# STM32H573 register map
File version: 1.8
CPU: CM33 r0p0, little endian, MPU, FPU, 4 interrupt priority bits
Registers are 32-bit, read-write, reset 0x0 unless marked. A register's access mark holds for its fields unless they carry their own. Offsets are from the block's base; [hi:lo] are bit positions; lines under a group give offsets from that group; {n}, {i} and the like mark numbered series; 'fields as' and 'values as' point back to an identical list.

## GPDMA1 — General purpose direct memory access controller
Base 0x40020000
Same registers: GPDMA2 0x40021000, SEC_GPDMA1 0x50020000, SEC_GPDMA2 0x50021000
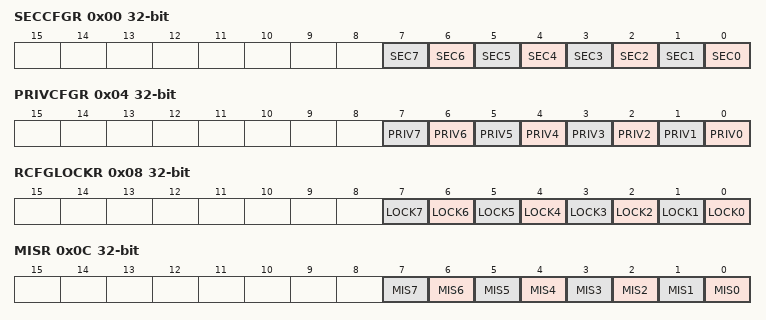
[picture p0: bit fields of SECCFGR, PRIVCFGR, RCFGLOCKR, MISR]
0x00 SECCFGR — GPDMA secure configuration register
  [n] SEC{n} (n=0..7) — secure state of channel x (x = 7 to 0)
0x04 PRIVCFGR — GPDMA privileged configuration register
  [n] PRIV{n} (n=0..7) — privileged state of channel x (x = 7 to 0)
    0=Unprivileged (Channel is unprivileged); 1=Privileged (Channel is privileged)
0x08 RCFGLOCKR — GPDMA configuration lock register
  [n] LOCK{n} (n=0..7) — lock the configuration of GPDMA_SECCFGR.SECx and GPDMA_PRIVCFGR.PRIVx, until a global GPDMA reset (x = 7 to 0) This bit is cleared after reset and, once set, it cannot be reset until a global GPDMA reset.
0x0C MISR ro — GPDMA non-secure masked interrupt status register
  [n] MIS{n} (n=0..7) — masked interrupt status of channel x (x = 7 to 0)
    0=NoTrigger (No interrupt has occurred on channel); 1=Trigger (An interrupt has occurred on channel)
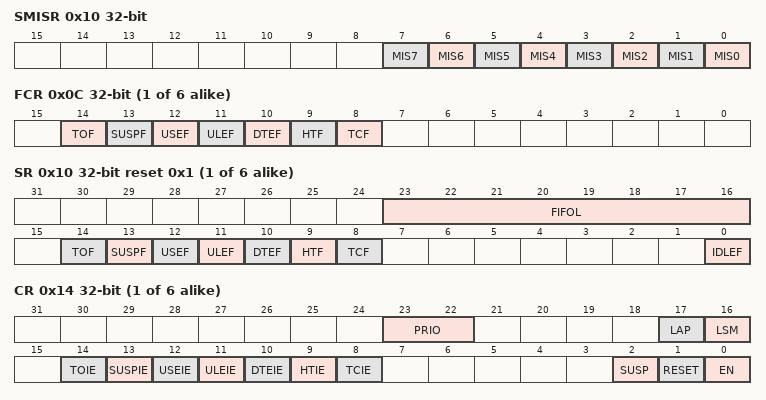
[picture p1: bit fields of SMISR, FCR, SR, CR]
0x10 SMISR ro — GPDMA secure masked interrupt status register
  [n] MIS{n} (n=0..7) — masked interrupt status of the secure channel x (x = 7 to 0)
{0x50+0x80*i} CH{i} (i=0..5) group — Channel cluster
  0x00 LBAR — GPDMA channel 0 linked-list base address register
    [31:16] LBA — linked-list base address of GPDMA channel x
  0x0C FCR wo — GPDMA channel 0 flag clear register
    [all] fields
      1=Clear flag
    [14] TOF — trigger overrun flag clear
    [13] SUSPF — completed suspension flag clear
    [12] USEF — user setting error flag clear
    [11] ULEF — update link transfer error flag clear
    [10] DTEF — data transfer error flag clear
    [9] HTF — half transfer flag clear
    [8] TCF — transfer complete flag clear
  0x10 SR ro reset 0x1 — GPDMA channel 0 status register
    [23:16] FIFOL — monitored FIFO level Number of available write beats in the FIFO, in units of the programmed destination data width (see GPDMA_CxTR1.DDW_LOG2[1:0], in units of bytes, half-words, or words). Note: After having suspended an active transfer, the user may need to read FIFOL[7:0], additionally to GPDMA_CxBR1.BDNT[15:0] and GPDMA_CxBR1.BRC[10:0], to know how many data have been transferred to the destination. Before reading, the user may wait for the transfer to be suspended (GPDMA_CxSR.SUSPF = 1).
    [14] TOF — trigger overrun flag
      0=NoTrigger (Event not triggered); 1=Trigger (Event triggered)
    [13] SUSPF — completed suspension flag
      values as TOF
    [12] USEF — user setting error flag
      values as TOF
    [11] ULEF — update link transfer error flag
      values as TOF
    [10] DTEF — data transfer error flag
      values as TOF
    [9] HTF — half transfer flag A half transfer event is either a half block transfer or a half 2D/repeated block transfer, depending on the transfer complete event mode (GPDMA_CxTR2.TCEM[1:0]). A half block transfer occurs when half of the bytes of the source block size (rounded up integer of GPDMA_CxBR1.BNDT[15:0]/2) has been transferred to the destination. A half 2D/repeated block transfer occurs when half of the repeated blocks (rounded up integer of (GPDMA_CxBR1.BRC[10:0]+1)/2)) has been transferred to the destination.
      values as TOF
    [8] TCF — transfer complete flag A transfer complete event is either a block transfer complete, a 2D/repeated block transfer complete, a LLI transfer complete including the upload of the next LLI if any, or the full linked-list completion, depending on the transfer complete event mode (GPDMA_CxTR2.TCEM[1:0]).
      values as TOF
    [0] IDLEF — idle flag This idle flag is de-asserted by hardware when the channel is enabled (GPDMA_CxCR.EN = 1) with a valid channel configuration (no USEF to be immediately reported). This idle flag is asserted after hard reset or by hardware when the channel is back in idle state (in suspended or disabled state).
      values as TOF
  0x14 CR access per field — GPDMA channel 0 control register
    [23:22] PRIO rw — priority level of the channel x GPDMA transfer versus others Note: This bit must be written when EN = 0. This bit is read-only when EN = 1.
      0=LowPrioLowWeight (Low priority, low weight); 1=LowPrioMidWeight (Low priority, mid weight); 2=LowPrioHighWeight (Low priority, high weight); 3=High priority
    [17] LAP rw — linked-list allocated port This bit is used to allocate the master port for the update of the GPDMA linked-list registers from the memory. Note: This bit must be written when EN=0. This bit is read-only when EN=1.
      0=Port 0 (AHB) allocated; 1=Port 1 (AHB) allocated
    [16] LSM rw — Link step mode First the (possible 1D/repeated) block transfer is executed as defined by the current internal register file until GPDMA_CxBR1.BNDT[15:0] = 0 and GPDMA_CxBR1.BRC[10:0] = 0 if present. Secondly the next linked-list data structure is conditionally uploaded from memory as defined by GPDMA_CxLLR. Then channel execution is completed. Note: This bit must be written when EN=0. This bit is read-only when EN=1.
      0=FullLinkedList (Channel executed for full linked list); 1=Once (Channel executed once for current linked list)
    [14] TOIE rw — trigger overrun interrupt enable
      0=Disabled (Interrupt disabled); 1=Enabled (Interrupt enabled)
    [13] SUSPIE rw — completed suspension interrupt enable
      values as TOIE
    [12] USEIE rw — user setting error interrupt enable
      values as TOIE
    [11] ULEIE rw — update link transfer error interrupt enable
      values as TOIE
    [10] DTEIE rw — data transfer error interrupt enable
      values as TOIE
    [9] HTIE rw — half transfer complete interrupt enable
      values as TOIE
    [8] TCIE rw — transfer complete interrupt enable
      values as TOIE
    [2] SUSP rw — suspend Writing 1 into the field RESET (bit 1) causes the hardware to de-assert this bit, whatever is written into this bit 2. Else: Software must write 1 in order to suspend an active channel i.e. a channel with an ongoing GPDMA transfer over its master ports. The software must write 0 in order to resume a suspended channel, following the programming sequence detailed in .
      0=NotSuspended (Channel operation not suspended); 1=Suspended (Channel operation suspended)
    [1] RESET wo — reset This bit is write only. Writing 0 has no impact. Writing 1 implies the reset of the following: the FIFO, the channel internal state, SUSP and EN bits (whatever is written receptively in bit 2 and bit 0). The reset is effective when the channel is in steady state, meaning one of the following: - active channel in suspended state (GPDMA_CxSR.SUSPF = 1 and GPDMA_CxSR.IDLEF = GPDMA_CxCR.EN = 1) - channel in disabled state (GPDMA_CxSR.IDLEF = 1 and GPDMA_CxCR.EN = 0). After writing a RESET, to continue using this channel, the user must explicitly reconfigure the channel including the hardware-modified configuration registers (GPDMA_CxBR1, GPDMA_CxSAR and GPDMA_CxDAR) before enabling again the channel (see the programming sequence in ).
      1=Reset channel
    [0] EN rw — enable Writing 1 into the field RESET (bit 1) causes the hardware to de-assert this bit, whatever is written into this bit 0. Else: this bit is de-asserted by hardware when there is a transfer error (master bus error or user setting error) or when there is a channel transfer complete (channel ready to be configured, e.g. if LSM=1 at the end of a single execution of the LLI). Else, this bit can be asserted by software. Writing 0 into this EN bit is ignored.
      0=Disabled (Channel disabled); 1=Enabled (Channel enabled)
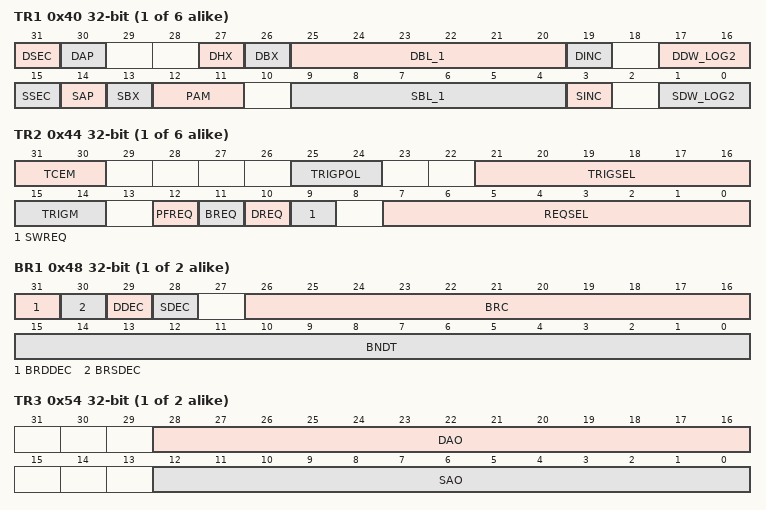
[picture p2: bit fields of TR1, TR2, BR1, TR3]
  0x40 TR1 — GPDMA channel 0 transfer register 1
    [31] DSEC — security attribute of the GPDMA transfer to the destination If GPDMA_SECCFGR.SECx = 1 and the access is secure: This is a secure register bit. This bit can only be read by a secure software. This bit must be written by a secure software when GPDMA_SECCFGR.SECx = 1. A secure write is ignored when GPDMA_SECCFGR.SECx = 0. When GPDMA_SECCFGR.SECx is de-asserted, this DSEC bit is also de-asserted by hardware (on a secure reconfiguration of the channel as non-secure), and the GPDMA transfer to the destination is non-secure.
    [30] DAP — destination allocated port This bit is used to allocate the master port for the destination transfer Note: This bit must be written when EN = 0. This bit is read-only when EN = 1.
      0=Port 0 (AHB) allocated; 1=Port 1 (AHB) allocated
    [27] DHX — destination half-word exchange If the destination data size is shorter than a word, this bit is ignored. If the destination data size is a word:
      0=NotExchanged (No halfword-based exchange within word); 1=Exchanged (The two consecutive (post PAM) half-words are exchanged in each destination word)
    [26] DBX — destination byte exchange If the destination data size is a byte, this bit is ignored. If the destination data size is not a byte:
      0=NotExchanged (No byte-based exchanged within word); 1=Exchanged (The two consecutive (post PAM) bytes are exchanged in each destination half-word)
    [25:20] DBL_1 — destination burst length minus 1, between 0 and 63 The burst length unit is one data named beat within a burst. If DBL_1[5:0] =0 , the burst can be named as single. Each data/beat has a width defined by the destination data width DDW_LOG2[1:0]. Note: If a burst transfer crossed a 1-Kbyte address boundary on a AHB transfer, the GPDMA modifies and shortens the programmed burst into singles or bursts of lower length, to be compliant with the AHB protocol. If a burst transfer is of length greater than the FIFO size of the channel x, the GPDMA modifies and shortens the programmed burst into singles or bursts of lower length, to be compliant with the FIFO size. Transfer performance is lower, with GPDMA re-arbitration between effective and lower singles/bursts, but the data integrity is guaranteed.
    [19] DINC — destination incrementing burst The destination address, pointed by GPDMA_CxDAR, is kept constant after a burst beat/single transfer, or is incremented by the offset value corresponding to a contiguous data after a burst beat/single transfer.
      0=FixedBurst; 1=Contiguously incremented burst
    [17:16] DDW_LOG2 — binary logarithm of the destination data width of a burst, in bytes Note: Setting a 8-byte data width causes a user setting error to be reported and none transfer is issued. A destination burst transfer must have an aligned address with its data width (start address GPDMA_CxDAR[2:0] and address offset GPDMA_CxTR3.DAO[2:0], versus DDW_LOG2[1:0]). Otherwise a user setting error is reported and no transfer is issued.
      on read: 0=Byte; 1=Half-word (2 bytes); 2=Word (4 bytes); 3=Error (User setting error) | on write: 0=Byte; 1=Half-word (2 bytes); 2=Word (4 bytes)
    [15] SSEC — security attribute of the GPDMA transfer from the source If GPDMA_SECCFGR.SECx = 1 and the access is secure: This is a secure register bit. This bit can only be read by a secure software. This bit must be written by a secure software when GPDMA_SECCFGR.SECx =1 . A secure write is ignored when GPDMA_SECCFGR.SECx = 0. When GPDMA_SECCFGR.SECx is de-asserted, this SSEC bit is also de-asserted by hardware (on a secure reconfiguration of the channel as non-secure), and the GPDMA transfer from the source is non-secure.
    [14] SAP — source allocated port This bit is used to allocate the master port for the source transfer Note: This bit must be written when EN = 0. This bit is read-only when EN = 1.
      0=Port 0 (AHB) allocated; 1=Port 1 (AHB) allocated
    [13] SBX — source byte exchange within the unaligned half-word of each source word If the source data width is shorter than a word, this bit is ignored. If the source data width is a word:
      values as DBX
    [12:11] PAM — padding/alignment mode If DDW_LOG2[1:0] = SDW_LOG2[1:0]: if the data width of a burst destination transfer is equal to the data width of a burst source transfer, these bits are ignored. Else, in the following enumerated values, the condition PAM_1 is when destination data width is higher that source data width, and the condition PAM_2 is when destination data width is higher than source data width. 1x: successive source data are FIFO queued and packed at the destination data width, in a left (LSB) to right (MSB) order (named little endian), before a destination transfer 1x: source data is FIFO queued and unpacked at the destination data width, to be transferred in a left (LSB) to right (MSB) order (named little endian) to the destination Note: If the transfer from the source peripheral is configured with peripheral flow-control mode (SWREQ = 0 and PFREQ = 1 and DREQ = 0), and if the destination data width the source data width, packing is not supported.
    [9:4] SBL_1 — source burst length minus 1, between 0 and 63 The burst length unit is one data named beat within a burst. If SBL_1[5:0] =0 , the burst can be named as single. Each data/beat has a width defined by the destination data width SDW_LOG2[1:0]. Note: If a burst transfer crossed a 1-Kbyte address boundary on a AHB transfer, the GPDMA modifies and shortens the programmed burst into singles or bursts of lower length, to be compliant with the AHB protocol. If a burst transfer is of length greater than the FIFO size of the channel x, the GPDMA modifies and shortens the programmed burst into singles or bursts of lower length, to be compliant with the FIFO size. Transfer performance is lower, with GPDMA re-arbitration between effective and lower singles/bursts, but the data integrity is guaranteed.
    [3] SINC — source incrementing burst The source address, pointed by GPDMA_CxSAR, is kept constant after a burst beat/single transfer or is incremented by the offset value corresponding to a contiguous data after a burst beat/single transfer.
      0=FixedBurst; 1=Contiguously incremented burst
    [1:0] SDW_LOG2 — binary logarithm of the source data width of a burst in bytes Note: Setting a 8-byte data width causes a user setting error to be reported and no transfer is issued. A source block size must be a multiple of the source data width (GPDMA_CxBR1.BNDT[2:0] versus SDW_LOG2[1:0]). Otherwise, a user setting error is reported and no transfer is issued. A source burst transfer must have an aligned address with its data width (start address GPDMA_CxSAR[2:0] versus SDW_LOG2[1:0]). Otherwise, a user setting error is reported and none transfer is issued.
      values as DDW_LOG2
  0x44 TR2 — GPDMA channel 0 transfer register 2
    [31:30] TCEM — transfer complete event mode These bits define the transfer granularity for the transfer complete and half transfer complete events generation. Note: If the initial LLI0 data transfer is null/void (directly programmed by the internal register file with GPDMA_CxBR1.BNDT[15:0] = 0), then neither the complete transfer event nor the half transfer event is generated. Note: If the initial LLI0 data transfer is null/void (directly programmed by the internal register file with GPDMA_CxBR1.BNDT[15:0] = 0), then neither the complete transfer event nor the half transfer event is generated. Note: If the initial LLI0 data transfer is null/void (i.e. directly programmed by the internal register file with GPDMA_CxBR1.BNDT[15:0] =0 ), then the half transfer event is not generated, and the transfer complete event is generated when is completed the loading of the LLI1.
      0=BlockLevel (At block level: the complete (and the half) transfer event is generated at the (respectively half of the) end of a block); 2=LliLevel (At LLI level: the complete transfer event is generated at the end of the LLI transfer. The half transfer event is generated at the half of the LLI data transfer); 3=ChannelLevel (At channel level: the complete transfer event is generated at the end of the last LLI transfer. The half transfer event is generated at the half of the data transfer of the last LLI)
    [25:24] TRIGPOL — trigger event polarity These bits define the polarity of the selected trigger event input defined by TRIGSEL[5:0].
      0=NoTrigger; 1=RisingEdge (Trigger on rising edge); 2=FallingEdge (Trigger on falling edge)
    [21:16] TRIGSEL — trigger event input selection These bits select the trigger event input of the GPDMA transfer (as per ), with an active trigger event if TRIGPOL[1:0] different 00.
      {v}=EXTI{v} (exti{v} is trigger input) (v=0..7); 8=TAMP_TRG1 (tamp_trg1 is trigger input); 9=TAMP_TRG2 (tamp_trg2 is trigger input); 11=LPTIM1_CH1 (lptim1_ch1 is trigger input); 12=LPTIM1_CH2 (lptim1_ch2 is trigger input); 13=LPTIM2_CH1 (lptim2_ch1 is trigger input); 14=LPTIM2_CH2 (lptim2_ch2 is trigger input); 15=RTC_ALRA_TRG (rtc_alra_trg is trigger input); 16=RTC_ALRB_TRG (rtc_alrb_trg is trigger input); 17=RTC_WUT_TRG (rtc_wut_trg is trigger input); {v}=GPDMA1_CH{v-18}_TC (gpdma1_ch{v-18}_tc is trigger input) (v=18..25); {v}=GPDMA2_CH{v-26}_TC (gpdma2_ch{v-26}_tc is trigger input) (v=26..33); 34=TIM2_TRG0 (tim2_trgo is trigger input); 44=COMP1_OUT (comp1_out is trigger input)
    [15:14] TRIGM — trigger mode These bits define the transfer granularity for its conditioning by the trigger. If the channel x is enabled (GPDMA_CxCR.EN asserted) with TRIGPOL[1:0] = 00 or 11, these TRIGM[1:0] bits are ignored. Else, a GPDMA transfer is conditioned by at least one trigger hit: first burst read of a 2D/repeated block transfer is conditioned by one hit trigger. If the peripheral is programmed as a source (DREQ = 0) of the LLI data transfer, each programmed burst read is conditioned. If the peripheral is programmed as a destination (DREQ = 1) of the LLI data transfer, each programmed burst write is conditioned. The first memory burst read of a (possibly 2D/repeated) block, also named as the first ready FIFO-based source burst, is gated by the occurrence of both the hardware request and the first trigger hit. The GPDMA monitoring of a trigger for channel x is started when the channel is enabled/loaded with a new active trigger configuration: rising or falling edge on a selected trigger (TRIGPOL[1:0] = 01 or respectively TRIGPOL[1:0] = 10). The monitoring of this trigger is kept active during the triggered and uncompleted (data or link) transfer; and if a new trigger is detected then, this hit is internally memorized to grant the next transfer, as long as the defined rising or falling edge is not modified, and the TRIGSEL[5:0] is not modified, and the channel is enabled. Transferring a next LLIn+1 that updates the GPDMA_CxTR2 with a new value for any of TRIGSEL[5:0] or TRIGPOL[1:0], resets the monitoring, trashing the memorized hit of the formerly defined LLIn trigger. After a first new trigger hitn+1 is memorized, if another second trigger hitn+2 is detected and if the hitn triggered transfer is still not completed, hitn+2 is lost and not memorized.memorized. A trigger overrun flag is reported (GPDMA_CxSR.TOF =1 ), and an interrupt is generated if enabled (GPDMA_CxCR.TOIE = 1). The channel is not automatically disabled by hardware due to a trigger overrun. Note: When the source block size is not a multiple of the source burst size and is a multiple of the source data width, then the last programmed source burst is not completed and is internally shorten to match the block size. In this case, if TRIGM[1:0] = 11 and (SWREQ =1 or (SWREQ = 0 and DREQ =0 )), the shortened burst transfer (by singles or/and by bursts of lower length) is conditioned once by the trigger. When the programmed destination burst is internally shortened by singles or/and by bursts of lower length (versus FIFO size, versus block size, 1-Kbyte boundary address crossing): if the trigger is conditioning the programmed destination burst (if TRIGM[1:0] = 11 and SWREQ = 0 and DREQ = 1), this shortened destination burst transfer is conditioned once by the trigger.
      0=BlockLevel (At block level: the first burst read of each block transfer is conditioned by one hit trigger); 2=LinkLevel (At link level: a LLI link transfer is conditioned by one hit trigger); 3=ProgrammedBurstLevel (At programmed burst level: programmed burst read is conditioned by one hit trigger.)
    [12] PFREQ — Hardware request in peripheral flow control mode Important: If a given channel x is not implemented with this feature, this bit is reserved and PFREQ is not present (see for the list of the implemented channels with this feature. If the channel x is activated (GPDMA_CxCR.EN asserted) with SWREQ = 1 (software request for a memory-to-memory transfer), this bit is ignored. Else: Note: In peripheral flow control mode, there are the following restrictions: - no 2D/repeated block support (GPDMA_CxBR1.BRC[10:0] must be set to 0 if present) - the peripheral must be set as the source of the transfer (DREQ = 0). - data packing to a wider destination width is not supported (if destination width source data width, GPDMA_CxTR1.PAM[1] must be set to 0). - GPDMA_CxBR1.BNDT[15:0] must be programmed as a multiple of the source (peripheral) burst size.
      0=GpdmaControlMode (The selected hardware request is driven by a peripheral with a hardware request/acknowledge protocol in GPDMA control mode); 1=PeripheralControlMode (The selected hardware request is driven by a peripheral with a hardware request/acknowledge protocol in peripheral control mode.)
    [11] BREQ — Block hardware request If the channel x is activated (GPDMA_CxCR.EN asserted) with SWREQ = 1 (software request for a memory-to-memory transfer), this bit is ignored. Else:
      0=Burst (The selected hardware request is driven by a peripheral with a hardware request/acknowledge protocol at a burst level); 1=Block (The selected hardware request is driven by a peripheral with a hardware request/acknowledge protocol at a block level)
    [10] DREQ — destination hardware request This bit is ignored if channel x is activated (GPDMA_CxCR.EN asserted) with SWREQ = 1 (software request for a memory-to-memory transfer). Else: Note: If the channel x is activated (GPDMA_CxCR.EN is asserted) with SWREQ = 0 and PFREQ = 1 (peripheral hardware request with peripheral flow-control mode), any software assertion to this DREQ bit is ignored: in peripheral flow-control mode, only a peripheral-to-memory transfer is supported.
      0=Source (Selected hardware request driven by a source peripheral); 1=Destination (Selected hardware request driven by a destination peripheral)
    [9] SWREQ — software request This bit is internally taken into account when GPDMA_CxCR.EN is asserted.
      0=Hardware (No software request. The selected hardware request REQSEL[7:0] is taken into account); 1=Software request for memory-to-memory transfer
    [7:0] REQSEL — GPDMA hardware request selection These bits are ignored if channel x is activated (GPDMA_CxCR.EN asserted) with SWREQ = 1 (software request for a memory-to-memory transfer). Else, the selected hardware request is internally taken into account as per . The user must not assign a same input hardware request (same REQSEL[7:0] value) to different active GPDMA channels (GPDMA_CxCR.EN = 1 and GPDMA_CxTR2.SWREQ = 0 for these channels). GPDMA is not intended to hardware support the case of simultaneous enabled channels incorrectly configured with a same hardware peripheral request signal, and there is no user setting error reporting.
      0=ADC1_DMA (adc1_dma selected); 2=DAC1_CH1_DMA (dac1_ch1_dma selected); 3=DAC1_CH2_DMA (dac1_ch2_dma selected); 4=TIM6_UPD_DMA (tim6_upd_dma selected); 5=TIM7_UPD_DMA (tim7_upd_dma selected); 6=SPI1_RX_DMA (spi1_rx_dma selected); 7=SPI1_TX_DMA (spi1_tx_dma selected); 8=SPI2_RX_DMA (spi2_rx_dma selected); 9=SPI2_TX_DMA (spi2_tx_dma selected); 10=SPI3_RX_DMA (spi3_rx_dma selected); 11=SPI3_TX_DMA (spi3_tx_dma selected); 12=I2C1_RX_DMA (i2c1_rx_dma selected); 13=I2C1_TX_DMA (i2c1_tx_dma selected); 15=I2C2_RX_DMA (i2c2_rx_dma selected); 16=I2C2_TX_DMA (i2c2_tx_dma selected); 18=I2C3_RX_DMA (i2c3_rx_dma selected); 19=I2C3_TX_DMA (i2c3_tx_dma selected); 21=USART1_RX_DMA (usart1_rx_dma selected); 22=USART1_TX_DMA (usart1_tx_dma selected); 23=USART2_RX_DMA (usart2_rx_dma selected); 24=USART2_TX_DMA (usart2_tx_dma selected); 25=USART3_RX_DMA (usart3_rx_dma selected); 26=USART3_TX_DMA (usart3_tx_dma selected); 27=UART4_RX_DMA (uart4_rx_dma selected); 28=UART4_TX_DMA (uart4_tx_dma selected); 29=UART5_RX_DMA (uart5_rx_dma selected); 30=UART5_TX_DMA (uart5_tx_dma selected); 31=USART6_RX_DMA (usart6_rx_dma selected); 32=USART6_TX_DMA (usart6_tx_dma selected); 33=UART7_RX_DMA (uart7_rx_dma selected); 34=UART7_TX_DMA (uart7_tx_dma selected); 35=UART8_RX_DMA (uart8_rx_dma selected); 36=UART8_TX_DMA (uart8_tx_dma selected); 37=UART9_RX_DMA (uart9_rx_dma selected); 38=UART9_TX_DMA (uart9_tx_dma selected); 39=UART10_RX_DMA (uart10_rx_dma selected); 40=UART10_TX_DMA (uart10_tx_dma selected); 41=UART11_RX_DMA (uart11_rx_dma selected); 42=UART11_TX_DMA (uart11_tx_dma selected); 43=UART12_RX_DMA (uart12_rx_dma selected); 44=UART12_TX_DMA (uart12_tx_dma selected); 45=LPUART1_RX_DMA (lpuart1_rx_dma selected); 46=LPUART1_TX_DMA (lpuart1_tx_dma selected); 47=SPI4_RX_DMA (spi4_rx_dma selected); 48=SPI4_TX_DMA (spi4_tx_dma selected); 49=SPI5_RX_DMA (spi5_rx_dma selected); 50=SPI5_TX_DMA (spi5_tx_dma selected); 51=SPI6_RX_DMA (spi6_rx_dma selected); 52=SPI6_TX_DMA (spi6_tx_dma selected); 53=SAI1_A_DMA (sai1_a_dma selected); 54=SAI1_B_DMA (sai1_b_dma selected); 55=SAI2_A_DMA (sai2_a_dma selected); 56=SAI2_B_DMA (sai2_b_dma selected); 57=OSPI1_DMA (ospi1_dma selected); {v}=TIM1_CC{v-57}_DMA (tim1_cc{v-57}_dma selected) (v=58..61); 62=TIM1_UPD_DMA (tim1_upd_dma selected); 63=TIM1_TRG_DMA (tim1_trg_dma selected); 64=TIM1_COM_DMA (tim1_com_dma selected); {v}=TIM8_CC{v-64}_DMA (tim8_cc{v-64}_dma selected) (v=65..68); 69=TIM8_UPD_DMA (tim8_upd_dma selected); 70=TIM8_TIG_DMA (tim8_tig_dma selected); 71=TIM8_COM_DMA (tim8_com_dma selected); {v}=TIM2_CC{v-71}_DMA (tim2_cc{v-71}_dma selected) (v=72..75); 76=TIM2_UPD_DMA (tim2_upd_dma selected); {v}=TIM3_CC{v-76}_DMA (tim3_cc{v-76}_dma selected) (v=77..80); 81=TIM3_UPD_DMA (tim3_upd_dma selected); 82=TIM3_TRG_DMA (tim3_trg_dma selected); {v}=TIM4_CC{v-82}_DMA (tim4_cc{v-82}_dma selected) (v=83..86); 87=TIM4_UPD_DMA (tim4_upd_dma selected); {v}=TIM5_CC{v-87}_DMA (tim5_cc{v-87}_dma selected) (v=88..91); 92=TIM5_UPD_DMA (tim5_upd_dma selected); 93=TIM5_TRG_DMA (tim5_trg_dma selected); 94=TIM15_CC1_DMA (tim15_cc1_dma selected); 95=TIM15_UPD_DMA (tim15_upd_dma selected); 96=TIM15_TRG_DMA (tim15_trg_dma selected); 97=TIM15_COM_DMA (tim15_com_dma selected); 98=TIM16_CC1_DMA (tim16_cc1_dma selected); 99=TIM16_UPD_DMA (tim16_upd_dma selected); 100=TIM17_CC1_DMA (tim17_cc1_dma selected); 101=TIM17_UPD_DMA (tim17_upd_dma selected); 102=LPTIM1_IC1_DMA (lptim1_ic1_dma selected); 103=LPTIM1_IC2_DMA (lptim1_ic2_dma selected); 104=LPTIM1_UE_DMA (lptim1_ue_dma selected); 105=LPTIM2_IC1_DMA (lptim2_ic1_dma selected); 106=LPTIM2_IC2_DMA (lptim2_ic2_dma selected); 107=LPTIM2_UE_DMA (lptim2_ue_dma selected); 108=DCMI_PSSI_DMA (dcmi_dma or pssi_dma(1) selected); 109=AES_OUT_DMA (aes_out_dma selected); 110=AES_IN_DMA (aes_in_dma selected); 111=HASH_IN_DMA (hash_in_dma selected); 112=UCPD1_RX_DMA (ucpd1_rx_dma selected); 113=UCPD1_TX_DMA (ucpd1_tx_dma selected); 114=CORDIC_READ_DMA (cordic_read_dma selected); 115=CORDIC_WRITE_DMA (cordic_write_dma selected); 116=FMAC_READ_DMA (fmac_read_dma selected); 117=FMAC_WRITE_DMA (fmac_write_dma selected); 118=SAES_OUT_DMA (saes_out_dma selected); 119=SAES_IN_DMA (saes_in_dma selected); 120=I3C1_RX_DMA (i3c1_rx_dma selected); 121=I3C1_TX_DMA (i3c1_tx_dma selected); 122=I3C1_TC_DMA (i3c1_tc_dma selected); 123=I3C1_RS_DMA (i3c1_rs_dma selected); 124=I2C4_RX_DMA (i2c4_rx_dma selected); 125=I2C4_TX_DMA (i2c4_tx_dma selected); 127=LPTIM3_IC1_DMA (lptim3_ic1_dma selected); 128=LPTIM3_IC2_DMA (lptim3_ic2_dma selected); 129=LPTIM3_UE_DMA (lptim3_ue_dma selected); 130=LPTIM5_IC1_DMA (lptim5_ic1_dma selected); 131=LPTIM5_IC2_DMA (lptim5_ic2_dma selected); 132=LPTIM5_UE_DMA (lptim5_ue_dma selected); 133=LPTIM6_IC1_DMA (lptim6_ic1_dma selected); 134=LPTIM6_IC2_DMA (lptim6_ic2_dma selected); 135=LPTIM6_UE_DMA (lptim6_ue_dma selected); 136=I3C2_RX (i3c2_rx selected); 137=I3C2_TX (i3c2_tx selected); 138=I3C2_TC (i3c2_tc selected); 139=I3C2_RS (i3c2_rs selected)
  0x48 BR1 — GPDMA channel 0 block register 1
    [15:0] BNDT — block number of data bytes to transfer from the source Block size transferred from the source. When the channel is enabled, this field becomes read-only and is decremented, indicating the remaining number of data items in the current source block to be transferred. BNDT[15:0] is programmed in number of bytes, maximum source block size is 64 Kbytes -1. Once the last data transfer is completed (BNDT[15:0] = 0): - if GPDMA_CxLLR.UB1 = 1, this field is updated by the LLI in the memory. - if GPDMA_CxLLR.UB1 = 0 and if there is at least one non null Uxx update bit, this field is internally restored to the programmed value. - if all GPDMA_CxLLR.Uxx = 0 and if GPDMA_CxLLR.LA[15:0] = 0, this field is internally restored to the programmed value (infinite/continuous last LLI). - if GPDMA_CxLLR = 0, this field is kept as zero following the last LLI data transfer. Note: A non-null source block size must be a multiple of the source data width (BNDT[2:0] versus GPDMA_CxTR1.SDW_LOG2[1:0]). Else a user setting error is reported and no transfer is issued. When configured in packing mode (GPDMA_CxTR1.PAM[1] = 1 and destination data width different from source data width), a non-null source block size must be a multiple of the destination data width (BNDT[2:0] versus GPDMA_CxTR1.DDW_LOG2[1:0]). Else a user setting error is reported and no transfer is issued.
  0x4C SAR — GPDMA channel 0 source address register
    [31:0] SA — source address This field is the pointer to the address from which the next data is read. During the channel activity, depending on the source addressing mode (GPDMA_CxTR1.SINC), this field is kept fixed or incremented by the data width (GPDMA_CxTR1.SDW_LOG2[1:0]) after each burst source data, reflecting the next address from which data is read. During the channel activity, this address is updated after each completed source burst, consequently to: the programmed source burst; either in fixed addressing mode or in contiguous-data incremented mode. If contiguously incremented (GPDMA_CxTR1.SINC = 1), then the additional address offset value is the programmed burst size, as defined by GPDMA_CxTR1.SBL_1[5:0] and GPDMA_CxTR1.SDW_LOG2[21:0] the additional source incremented/decremented offset value as programmed by GPDMA_CxBR1.SDEC and GPDMA_CxTR3.SAO[12:0] once/if completed source block transfer, for a channel x with 2D addressing capability (x = 12 to 15). additional block repeat source incremented/decremented offset value as programmed by GPDMA_CxBR1.BRSDEC and GPDMA_CxBR2.BRSAO[15:0] In linked-list mode, after a LLI data transfer is completed, this register is automatically updated by GPDMA from the memory, provided the LLI is set with GPDMA_CxLLR.USA = 1. Note: A source address must be aligned with the programmed data width of a source burst (SA[2:0] versus GPDMA_CxTR1.SDW_LOG2[1:0]). Else, a user setting error is reported and no transfer is issued. When the source block size is not a multiple of the source burst size and is a multiple of the source data width, the last programmed source burst is not completed and is internally shorten to match the block size. In this case, the additional GPDMA_CxTR3.SAO[12:0] is not applied.
  0x50 DAR — GPDMA channel 0 destination address register
    [31:0] DA — destination address This field is the pointer to the address from which the next data is written. During the channel activity, depending on the destination addressing mode (GPDMA_CxTR1.DINC), this field is kept fixed or incremented by the data width (GPDMA_CxTR1.DDW_LOG2[21:0]) after each burst destination data, reflecting the next address from which data is written. During the channel activity, this address is updated after each completed destination burst, consequently to: the programmed destination burst; either in fixed addressing mode or in contiguous-data incremented mode. If contiguously incremented (GPDMA_CxTR1.DINC = 1), then the additional address offset value is the programmed burst size, as defined by GPDMA_CxTR1.DBL_1[5:0] and GPDMA_CxTR1.DDW_LOG2[1:0] the additional destination incremented/decremented offset value as programmed by GPDMA_CxBR1.DDEC and GPDMA_CxTR3.DAO[12:0] once/if completed destination block transfer, for a channel x with 2D addressing capability (x = 12 to 15), the additional block repeat destination incremented/decremented offset value as programmed by GPDMA_CxBR1.BRDDEC and GPDMA_CxBR2.BRDAO[15:0] In linked-list mode, after a LLI data transfer is completed, this register is automatically updated by the GPDMA from the memory, provided the LLI is set with GPDMA_CxLLR.UDA = 1. Note: A destination address must be aligned with the programmed data width of a destination burst (DA[2:0] versus GPDMA_CxTR1.DDW_LOG2[1:0]). Else, a user setting error is reported and no transfer is issued.
  0x7C LLR — GPDMA channel 0 linked-list address register
    [31] UT1 — Update GPDMA_CxTR1 from memory This bit controls the update of GPDMA_CxTR1 from the memory during the link transfer.
      0=NoUpdate (No CxTR1 update); 1=Update (CxTR1 updated from memory during link transfer)
    [30] UT2 — Update GPDMA_CxTR2 from memory This bit controls the update of GPDMA_CxTR2 from the memory during the link transfer.
      0=NoUpdate (No CxTR2 update); 1=Update (CxTR2 updated from memory during link transfer)
    [29] UB1 — Update GPDMA_CxBR1 from memory This bit controls the update of GPDMA_CxBR1 from the memory during the link transfer. If UB1 = 0 and if GPDMA_CxLLR different 0, the linked-list is not completed. GPDMA_CxBR1.BNDT[15:0] is then restored to the programmed value after data transfer is completed and before the link transfer.
      0=NoUpdate (No CxBR1 update); 1=Update (CxBR1 updated from memory during link transfer)
    [28] USA — update GPDMA_CxSAR from memory This bit controls the update of GPDMA_CxSAR from the memory during the link transfer.
      0=NoUpdate (No CxSAR update); 1=Update (CxSAR updated from memory during link transfer)
    [27] UDA — Update GPDMA_CxDAR register from memory This bit is used to control the update of GPDMA_CxDAR from the memory during the link transfer.
      0=NoUpdate (No CxDAR update); 1=Update (CxDAR updated from memory during link transfer)
    [16] ULL — Update GPDMA_CxLLR register from memory This bit is used to control the update of GPDMA_CxLLR from the memory during the link transfer.
      0=NoUpdate (No CxLLR update); 1=Update (CxLLR updated from memory during link transfer)
    [15:2] LA — pointer (16-bit low-significant address) to the next linked-list data structure If UT1 = UT2 = UB1 = USA = UDA = ULL = 0 and if LA[15:20] = 0, the current LLI is the last one. The channel transfer is completed without any update of the linked-list GPDMA register file. Else, this field is the pointer to the memory address offset from which the next linked-list data structure is automatically fetched from, once the data transfer is completed, in order to conditionally update the linked-list GPDMA internal register file (GPDMA_CxCTR1, GPDMA_CxTR2, GPDMA_CxBR1, GPDMA_CxSAR, GPDMA_CxDAR and GPDMA_CxLLR). Note: The user must program the pointer to be 32-bit aligned. The two low-significant bits are write ignored.
{0x50+0x80*i} CH2D{i} (i=6..7) group — 2D-addressing channel cluster
  0x00 LBAR — GPDMA channel 6 linked-list base address register
    [31:16] LBA — linked-list base address of GPDMA channel x
  0x0C FCR wo — GPDMA channel 6 flag clear register
    fields as CH0.FCR
  0x10 SR ro reset 0x1 — GPDMA channel 6 status register
    fields as CH0.SR
  0x14 CR access per field — GPDMA channel 6 control register
    fields as CH0.CR
  0x40 TR1 — GPDMA channel 6 transfer register 1
    fields as CH0.TR1
  0x44 TR2 — GPDMA channel 6 transfer register 2
    fields as CH0.TR2
  0x48 BR1 — GPDMA channel 6 alternate block register 1
    [31] BRDDEC — Block repeat destination address decrement Note: On top of this increment/decrement (depending on BRDDEC), GPDMA_CxDAR is in the same time also updated by the increment/decrement (depending on DDEC) of the GPDMA_CxTR3.DAO value, as it is usually done at the end of each programmed burst transfer.
      0=Increment (Block repeat destination address incremented); 1=Decrement (Block repeat destination address decremented)
    [30] BRSDEC — Block repeat source address decrement Note: On top of this increment/decrement (depending on BRSDEC), GPDMA_CxSAR is in the same time also updated by the increment/decrement (depending on SDEC) of the GPDMA_CxTR3.SAO value, as it is done after any programmed burst transfer.
      0=Increment (Block repeat source address incremented); 1=Decrement (Block repeat source address decremented)
    [29] DDEC — destination address decrement
      0=Increment (Destination address incremented); 1=Decrement (Destination address decremented)
    [28] SDEC — source address decrement
      0=Increment (Source address incremented); 1=Decrement (Source address decremented)
    [26:16] BRC — Block repeat counter This field contains the number of repetitions of the current block (0 to 2047). When the channel is enabled, this field becomes read-only. After decrements, this field indicates the remaining number of blocks, excluding the current one. This counter is hardware decremented for each completed block transfer. Once the last block transfer is completed (BRC[10:0] = BNDT[15:0] = 0): If GPDMA_CxLLR.UB1 = 1, all GPDMA_CxBR1 fields are updated by the next LLI in the memory. If GPDMA_CxLLR.UB1 = 0 and if there is at least one not null Uxx update bit, this field is internally restored to the programmed value. if all GPDMA_CxLLR.Uxx = 0 and if GPDMA_CxLLR.LA[15:0] different 0, this field is internally restored to the programmed value (infinite/continuous last LLI). if GPDMA_CxLLR = 0, this field is kept as zero following the last LLI and data transfer.
    [15:0] BNDT — block number of data bytes to transfer from the source Block size transferred from the source. When the channel is enabled, this field becomes read-only and is decremented, indicating the remaining number of data items in the current source block to be transferred. BNDT[15:0] is programmed in number of bytes, maximum source block size is 64 Kbytes -1. Once the last data transfer is completed (BNDT[15:0] = 0): - if GPDMA_CxLLR.UB1 = 1, this field is updated by the LLI in the memory. - if GPDMA_CxLLR.UB1 = 0 and if there is at least one not null Uxx update bit, this field is internally restored to the programmed value. - if all GPDMA_CxLLR.Uxx = 0 and if GPDMA_CxLLR.LA[15:0] different 0, this field is internally restored to the programmed value (infinite/continuous last LLI). - if GPDMA_CxLLR = 0, this field is kept as zero following the last LLI data transfer. Note: A non-null source block size must be a multiple of the source data width (BNDT[2:0] versus GPDMA_CxTR1.SDW_LOG2[1:0]). Else a user setting error is reported and no transfer is issued. When configured in packing mode (GPDMA_CxTR1.PAM[1]=1 and destination data width different from source data width), a non-null source block size must be a multiple of the destination data width (BNDT[2:0] versus GPDMA_CxTR1.DDW_LOG2[1:0]). Else a user setting error is reported and no transfer is issued.
  0x4C SAR — GPDMA channel 6 source address register
    fields as CH0.SAR
  0x50 DAR — GPDMA channel 6 destination address register
    fields as CH0.DAR
  0x54 TR3 — GPDMA channel 6 transfer register 3
    [28:16] DAO range 0..4095 — destination address offset increment The destination address, pointed by GPDMA_CxDAR, is incremented or decremented (depending on GPDMA_CxBR1.DDEC) by this offset DAO[12:0] for each programmed destination burst. This offset is not including and is added to the programmed burst size when the completed burst is addressed in incremented mode (GPDMA_CxTR1.DINC = 1). Note: A destination address offset must be aligned with the programmed data width of a destination burst (DAO[2:0] versus GPDMA_CxTR1.DDW_LOG2[1:0]). Else, a user setting error is reported and no transfer is issued.
    [12:0] SAO range 0..4095 — source address offset increment The source address, pointed by GPDMA_CxSAR, is incremented or decremented (depending on GPDMA_CxBR1.SDEC) by this offset SAO[12:0] for each programmed source burst. This offset is not including and is added to the programmed burst size when the completed burst is addressed in incremented mode (GPDMA_CxTR1.SINC = 1). Note: A source address offset must be aligned with the programmed data width of a source burst (SAO[2:0] versus GPDMA_CxTR1.SDW_LOG2[1:0]). Else a user setting error is reported and none transfer is issued. When the source block size is not a multiple of the destination burst size and is a multiple of the source data width, then the last programmed source burst is not completed and is internally shorten to match the block size. In this case, the additional GPDMA_CxTR3.SAO[12:0] is not applied.
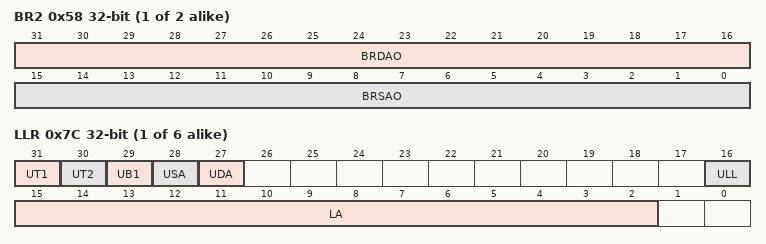
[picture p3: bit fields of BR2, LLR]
  0x58 BR2 — GPDMA channel 6 block register 2
    [31:16] BRDAO — Block repeated destination address offset For a channel with 2D addressing capability, this field is used to update (by addition or subtraction depending on GPDMA_CxBR1.BRDDEC) the current destination address (GPDMA_CxDAR) at the end of a block transfer. Note: A block repeated destination address offset must be aligned with the programmed data width of a destination burst (BRDAO[2:0] versus GPDMA_CxTR1.DDW_LOG2[1:0]). Else a user setting error is reported and no transfer is issued. BRDAO[15:0] must be set to 0 in peripheral flow-control mode (if GPDMA_CxTR2.PFREQ = 1).
    [15:0] BRSAO — Block repeated source address offset For a channel with 2D addressing capability, this field is used to update (by addition or subtraction depending on GPDMA_CxBR1.BRSDEC) the current source address (GPDMA_CxSAR) at the end of a block transfer. Note: A block repeated source address offset must be aligned with the programmed data width of a source burst (BRSAO[2:0] versus GPDMA_CxTR1.SDW_LOG2[1:0]). Else a user setting error is reported and no transfer is issued. BRSAO[15:0] must be set to 0 in peripheral flow-control mode (if GPDMA_CxTR2.PFREQ = 1).
  0x7C LLR — GPDMA channel 6 alternate linked-list address register
    [31] UT1 — Update GPDMA_CxTR1 from memory This bit controls the update of GPDMA_CxTR1 from the memory during the link transfer.
      values as CH0.LLR.UT1
    [30] UT2 — Update GPDMA_CxTR2 from memory This bit controls the update of GPDMA_CxTR2 from the memory during the link transfer.
      values as CH0.LLR.UT2
    [29] UB1 — Update GPDMA_CxBR1 from memory This bit controls the update of GPDMA_CxBR1 from the memory during the link transfer. If UB1 = 0 and if GPDMA_CxLLR different 0, the linked-list is not completed. GPDMA_CxBR1.BNDT[15:0] is then restored to the programmed value after data transfer is completed and before the link transfer.
      values as CH0.LLR.UB1
    [28] USA — update GPDMA_CxSAR from memory This bit controls the update of GPDMA_CxSAR from the memory during the link transfer.
      values as CH0.LLR.USA
    [27] UDA — Update GPDMA_CxDAR register from memory This bit is used to control the update of GPDMA_CxDAR from the memory during the link transfer.
      values as CH0.LLR.UDA
    [26] UT3 — Update GPDMA_CxTR3 from memory This bit controls the update of GPDMA_CxTR3 from the memory during the link transfer.
      0=NoUpdate (No CxTR3 update); 1=Update (CxTR3 updated from memory during link transfer)
    [25] UB2 — Update GPDMA_CxBR2 from memory This bit controls the update of GPDMA_CxBR2 from the memory during the link transfer.
      0=NoUpdate (No CxBR2 update); 1=Update (CxBR2 updated from memory during link transfer)
    [16] ULL — Update GPDMA_CxLLR register from memory This bit is used to control the update of GPDMA_CxLLR from the memory during the link transfer.
      values as CH0.LLR.ULL
    [15:2] LA — pointer (16-bit low-significant address) to the next linked-list data structure If UT1 = UT2 = UB1 = USA = UDA = ULL = 0 and if LA[15:20] = 0, the current LLI is the last one. The channel transfer is completed without any update of the linked-list GPDMA register file. Else, this field is the pointer to the memory address offset from which the next linked-list data structure is automatically fetched from, once the data transfer is completed, in order to conditionally update the linked-list GPDMA internal register file (GPDMA_CxCTR1, GPDMA_CxTR2, GPDMA_CxBR1, GPDMA_CxSAR, GPDMA_CxDAR and GPDMA_CxLLR). Note: The user must program the pointer to be 32-bit aligned. The two low-significant bits are write ignored.
